# EFR32BG22E224F512IM40 register map
Vendor: Silicon Labs; Series: EFR32; File version: F
Registers are 32-bit, read-write, reset 0x0 unless marked. A register's access mark holds for its fields unless they carry their own. Offsets are from the block's base; [hi:lo] are bit positions; {n}, {i} and the like mark numbered series; 'fields as' and 'values as' point back to an identical list.

## BURAM_NS — BURAM_NS Registers
Base 0x50080000
Same registers: BURAM_S 0x40080000
{0x0+4i} RET{i}_REG (i=0..31)
  [31:0] RETREG — Latch based Retention register

## BURTC_NS — BURTC_NS Registers
Base 0x50064000
Same registers: BURTC_S 0x40064000
0x00 IPVERSION ro
  [31:0] IPVERSION — IP Version ID
0x04 EN
  [0] EN — BURTC Enable
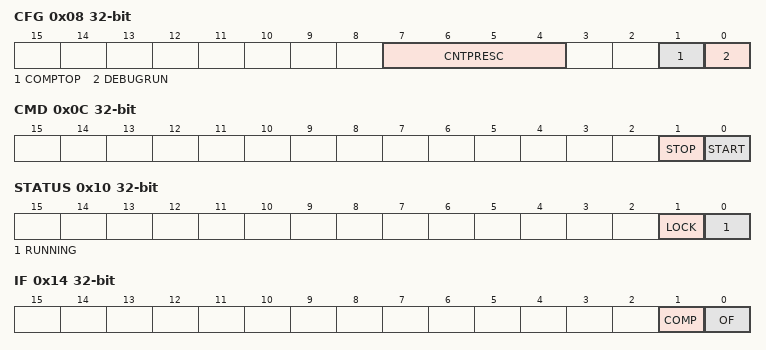
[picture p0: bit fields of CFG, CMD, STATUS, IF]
0x08 CFG
  [7:4] CNTPRESC — Counter prescaler value.
    0=DIV1 (CLK_CNT = (BURTC LF CLK)/1); 1=DIV2 (CLK_CNT = (BURTC LF CLK)/2); 2=DIV4 (CLK_CNT = (BURTC LF CLK)/4); 3=DIV8 (CLK_CNT = (BURTC LF CLK)/8); 4=DIV16 (CLK_CNT = (BURTC LF CLK)/16); 5=DIV32 (CLK_CNT = (BURTC LF CLK)/32); 6=DIV64 (CLK_CNT = (BURTC LF CLK)/64); 7=DIV128 (CLK_CNT = (BURTC LF CLK)/128); 8=DIV256 (CLK_CNT = (BURTC LF CLK)/256); 9=DIV512 (CLK_CNT = (BURTC LF CLK)/512); 10=DIV1024 (CLK_CNT = (BURTC LF CLK)/1024); 11=DIV2048 (CLK_CNT = (BURTC LF CLK)/2048); 12=DIV4096 (CLK_CNT = (BURTC LF CLK)/4096); 13=DIV8192 (CLK_CNT = (BURTC LF CLK)/8192); 14=DIV16384 (CLK_CNT = (BURTC LF CLK)/16384); 15=DIV32768 (CLK_CNT = (BURTC LF CLK)/32768)
  [1] COMPTOP — Compare Channel is Top Value
    0=DISABLE (The top value of the BURTC is 4294967295 (0xFFFFFFFF)); 1=ENABLE (The top value of the BURTC is given by COMP)
  [0] DEBUGRUN — Debug Mode Run Enable
    0=DISABLE (BURTC is frozen in debug mode); 1=ENABLE (BURTC is running in debug mode)
0x0C CMD wo
  [1] STOP — Stop BURTC counter
  [0] START — Start BURTC counter
0x10 STATUS ro
  [1] LOCK — Configuration Lock Status
    0=UNLOCKED (All BURTC lockable registers are unlocked.); 1=LOCKED (All BURTC lockable registers are locked.)
  [0] RUNNING — BURTC running status
0x14 IF
  [1] COMP — Compare Match Interrupt Flag
  [0] OF — Overflow Interrupt Flag
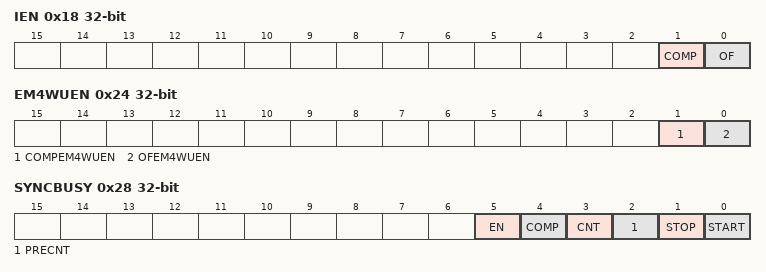
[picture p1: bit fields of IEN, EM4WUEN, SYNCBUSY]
0x18 IEN
  fields as IF
0x1C PRECNT
  [14:0] PRECNT — Pre-Counter Value
0x20 CNT
  [31:0] CNT — Counter Value
0x24 EM4WUEN
  [1] COMPEM4WUEN — Compare Match EM4 Wakeup Enable
  [0] OFEM4WUEN — Overflow EM4 Wakeup Enable
0x28 SYNCBUSY ro
  [5] EN — Sync busy for EN
  [4] COMP — Sync busy for COMP
  [3] CNT — Sync busy for CNT
  [2] PRECNT — Sync busy for PRECNT
  [1] STOP — Sync busy for STOP
  [0] START — Sync busy for START
0x2C LOCK wo reset 0xAEE8
  [15:0] LOCKKEY — Configuration Lock Key
    0xAEE8=UNLOCK (Write to unlock all BURTC lockable registers)
0x30 COMP
  [31:0] COMP — Compare Value

## CRYPTOACC_NS_PKCTRL — CRYPTOACC_NS_PKCTRL Registers
Base 0x5C022000
Same registers: CRYPTOACC_S_PKCTRL 0x4C022000
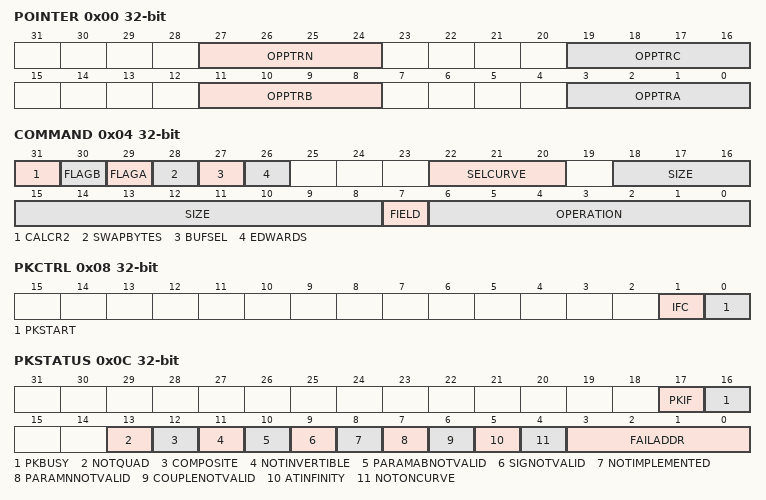
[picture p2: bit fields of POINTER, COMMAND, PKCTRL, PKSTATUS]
0x00 POINTER
  [27:24] OPPTRN, [19:16] OPPTRC, [11:8] OPPTRB, [3:0] OPPTRA
0x04 COMMAND
  [31] CALCR2 — Calculate R2
    0=FALSE (don't recalculate R² mod N); 1=TRUE (re-calculate R² mod N)
  [30] FLAGB
  [29] FLAGA
  [28] SWAPBYTES
    0=NATIVE (Native format (little endian)); 1=SWAPPED (Byte swapped (big endian))
  [27] BUFSEL — Buffer Select
    0=MEM0 (use data in data memory 0)
  [26] EDWARDS — Edwards Curve Enable
  [22:20] SELCURVE — Select Curve
    0=NONE (No acceleration); 1=P256; 4=P192
  [18:8] SIZE — Size of Operands in data memory
  [7] FIELD
    0=GFP (Field is GF(p)); 1=GF2M (Field is GF(2^m))
  [6:0] OPERATION — Type of Operation
0x08 PKCTRL wo
  [1] IFC — ClearIRQ
  [0] PKSTART
0x0C PKSTATUS ro
  [17] PKIF — Interrupt status
  [16] PKBUSY
  [13] NOTQUAD — Not quadratic residue
  [12] COMPOSITE
    0=FALSE (random number under test is probably prime); 1=TRUE (random number under test is composite)
  [11] NOTINVERTIBLE
  [10] PARAMABNOTVALID
  [9] SIGNOTVALID — Signature not valid
  [8] NOTIMPLEMENTED
  [7] PARAMNNOTVALID
  [6] COUPLENOTVALID
  [5] ATINFINITY — Point Px at infinity
  [4] NOTONCURVE — Point Px not on curve
  [3:0] FAILADDR — Fail Address
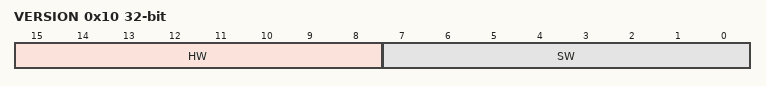
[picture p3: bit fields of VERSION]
0x10 VERSION ro
  [15:8] HW — Hardware version number
  [7:0] SW — Software version number
0x14 TIMER ro
